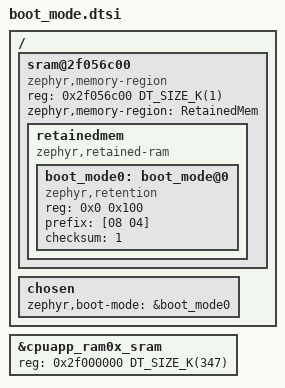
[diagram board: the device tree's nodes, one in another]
/*
 * Retained-RAM boot mode region, shared by MCUboot and the application.
 *
 * Copyright (c) 2026 Nordic Semiconductor ASA
 * SPDX-License-Identifier: LicenseRef-Nordic-5-Clause
 *
 * Included from the application board overlay and the MCUboot board overlay.
 * Both images must describe this region identically.
 */

&cpuapp_ram0x_sram {
	reg = <0x2f000000 DT_SIZE_K(347)>;
	ranges = <0x0 0x2f000000 0x56c00>;
};

/ {
	sram@2f056c00 {
		compatible = "zephyr,memory-region", "mmio-sram";
		reg = <0x2f056c00 DT_SIZE_K(1)>;
		zephyr,memory-region = "RetainedMem";
		status = "okay";

		retainedmem {
			compatible = "zephyr,retained-ram";
			status = "okay";
			#address-cells = <1>;
			#size-cells = <1>;

			boot_mode0: boot_mode@0 {
				compatible = "zephyr,retention";
				status = "okay";
				reg = <0x0 0x100>;
				prefix = [08 04];
				checksum = <1>;
			};
		};
	};

	chosen {
		zephyr,boot-mode = &boot_mode0;
	};
};
